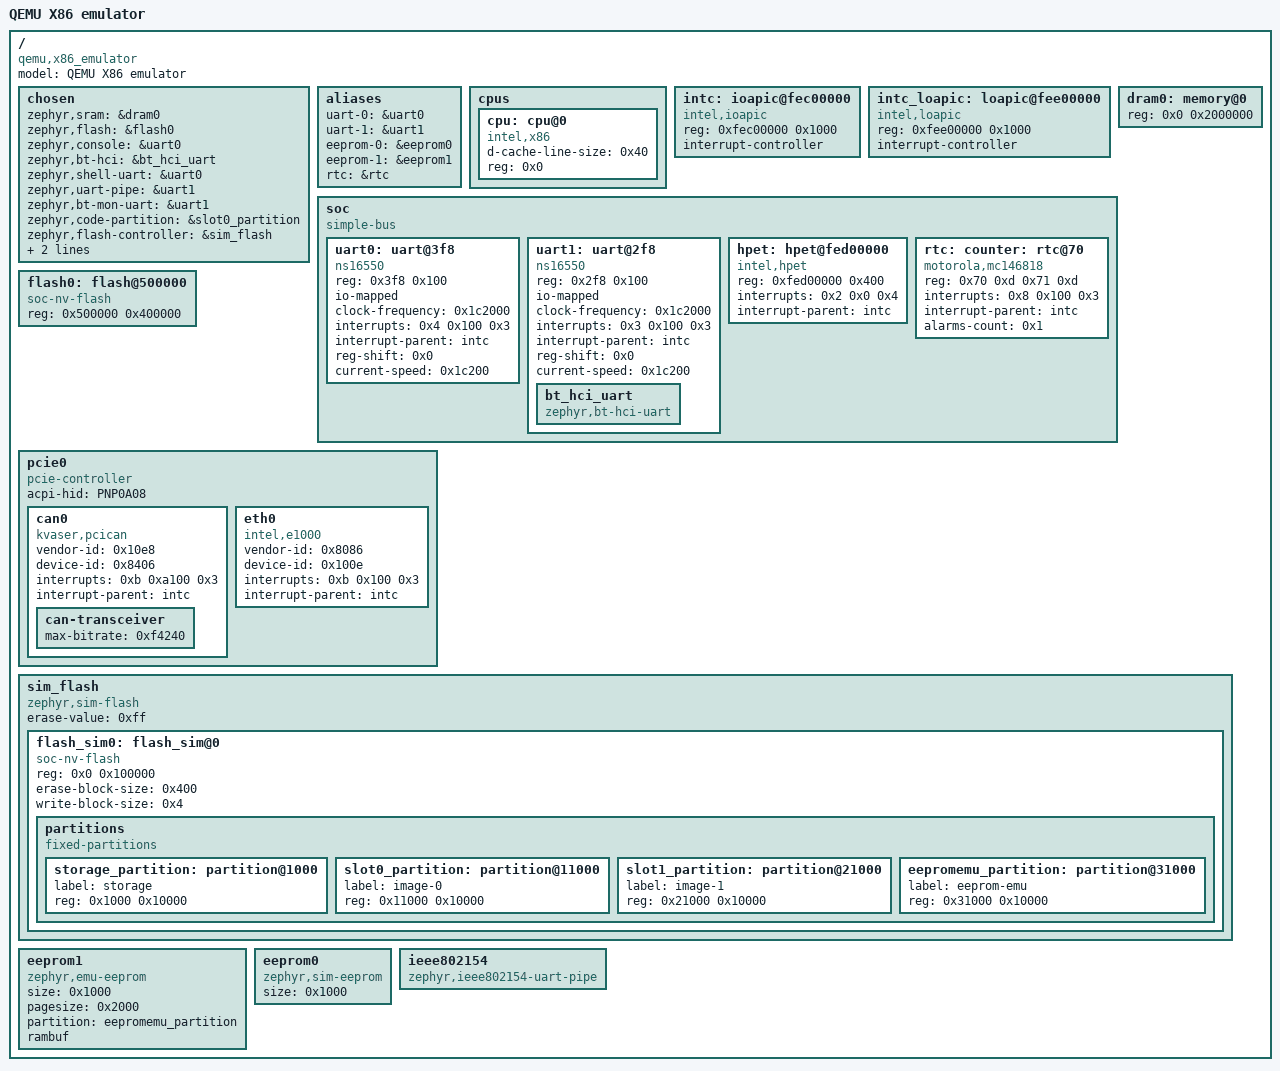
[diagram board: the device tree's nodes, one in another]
/dts-v1/;

/ {
	#address-cells = < 0x1 >;
	#size-cells = < 0x1 >;
	model = "QEMU X86 emulator";
	compatible = "qemu,x86_emulator";
	chosen {
		zephyr,sram = &dram0;
		zephyr,flash = &flash0;
		zephyr,console = &uart0;
		zephyr,bt-hci = &bt_hci_uart;
		zephyr,shell-uart = &uart0;
		zephyr,uart-pipe = &uart1;
		zephyr,bt-mon-uart = &uart1;
		zephyr,code-partition = &slot0_partition;
		zephyr,flash-controller = &sim_flash;
		zephyr,ieee802154 = &ieee802154;
		zephyr,canbus = &can0;
	};
	aliases {
		uart-0 = &uart0;
		uart-1 = &uart1;
		eeprom-0 = &eeprom0;
		eeprom-1 = &eeprom1;
		rtc = &rtc;
	};
	cpus {
		#address-cells = < 0x1 >;
		#size-cells = < 0x0 >;
		cpu: cpu@0 {
			device_type = "cpu";
			d-cache-line-size = < 0x40 >;
			reg = < 0x0 >;
			compatible = "intel,x86";
		};
	};
	intc: ioapic@fec00000 {
		compatible = "intel,ioapic";
		#address-cells = < 0x1 >;
		#interrupt-cells = < 0x3 >;
		reg = < 0xfec00000 0x1000 >;
		interrupt-controller;
		phandle = < 0x1 >;
	};
	intc_loapic: loapic@fee00000 {
		compatible = "intel,loapic";
		reg = < 0xfee00000 0x1000 >;
		interrupt-controller;
		#interrupt-cells = < 0x3 >;
		#address-cells = < 0x1 >;
	};
	dram0: memory@0 {
		device_type = "memory";
		reg = < 0x0 0x2000000 >;
	};
	soc {
		#address-cells = < 0x1 >;
		#size-cells = < 0x1 >;
		compatible = "simple-bus";
		ranges;
		uart0: uart@3f8 {
			compatible = "ns16550";
			reg = < 0x3f8 0x100 >;
			io-mapped;
			clock-frequency = < 0x1c2000 >;
			interrupts = < 0x4 0x100 0x3 >;
			interrupt-parent = < &intc >;
			reg-shift = < 0x0 >;
			status = "okay";
			current-speed = < 0x1c200 >;
		};
		uart1: uart@2f8 {
			compatible = "ns16550";
			reg = < 0x2f8 0x100 >;
			io-mapped;
			clock-frequency = < 0x1c2000 >;
			interrupts = < 0x3 0x100 0x3 >;
			interrupt-parent = < &intc >;
			reg-shift = < 0x0 >;
			status = "okay";
			current-speed = < 0x1c200 >;
			bt_hci_uart: bt_hci_uart {
				compatible = "zephyr,bt-hci-uart";
				status = "okay";
			};
		};
		hpet: hpet@fed00000 {
			compatible = "intel,hpet";
			reg = < 0xfed00000 0x400 >;
			interrupts = < 0x2 0x0 0x4 >;
			interrupt-parent = < &intc >;
			status = "okay";
		};
		rtc: counter: rtc@70 {
			compatible = "motorola,mc146818";
			reg = < 0x70 0xd 0x71 0xd >;
			interrupts = < 0x8 0x100 0x3 >;
			interrupt-parent = < &intc >;
			alarms-count = < 0x1 >;
			status = "okay";
		};
	};
	flash0: flash@500000 {
		compatible = "soc-nv-flash";
		reg = < 0x500000 0x400000 >;
	};
	pcie0: pcie0 {
		#address-cells = < 0x1 >;
		#size-cells = < 0x1 >;
		compatible = "pcie-controller";
		acpi-hid = "PNP0A08";
		ranges;
		can0: can0 {
			compatible = "kvaser,pcican";
			status = "okay";
			vendor-id = < 0x10e8 >;
			device-id = < 0x8406 >;
			interrupts = < 0xb 0xa100 0x3 >;
			interrupt-parent = < &intc >;
			can-transceiver {
				max-bitrate = < 0xf4240 >;
			};
		};
		eth0: eth0 {
			compatible = "intel,e1000";
			vendor-id = < 0x8086 >;
			device-id = < 0x100e >;
			interrupts = < 0xb 0x100 0x3 >;
			interrupt-parent = < &intc >;
			status = "okay";
		};
	};
	sim_flash: sim_flash {
		compatible = "zephyr,sim-flash";
		#address-cells = < 0x1 >;
		#size-cells = < 0x1 >;
		erase-value = < 0xff >;
		flash_sim0: flash_sim@0 {
			compatible = "soc-nv-flash";
			reg = < 0x0 0x100000 >;
			erase-block-size = < 0x400 >;
			write-block-size = < 0x4 >;
			partitions {
				compatible = "fixed-partitions";
				#address-cells = < 0x1 >;
				#size-cells = < 0x1 >;
				storage_partition: partition@1000 {
					label = "storage";
					reg = < 0x1000 0x10000 >;
				};
				slot0_partition: partition@11000 {
					label = "image-0";
					reg = < 0x11000 0x10000 >;
				};
				slot1_partition: partition@21000 {
					label = "image-1";
					reg = < 0x21000 0x10000 >;
				};
				eepromemu_partition: partition@31000 {
					label = "eeprom-emu";
					reg = < 0x31000 0x10000 >;
					phandle = < 0x2 >;
				};
			};
		};
	};
	eeprom1: eeprom1 {
		status = "okay";
		compatible = "zephyr,emu-eeprom";
		size = < 0x1000 >;
		pagesize = < 0x2000 >;
		partition = < &eepromemu_partition >;
		rambuf;
	};
	eeprom0: eeprom0 {
		status = "okay";
		compatible = "zephyr,sim-eeprom";
		size = < 0x1000 >;
	};
	ieee802154: ieee802154 {
		compatible = "zephyr,ieee802154-uart-pipe";
	};
};
